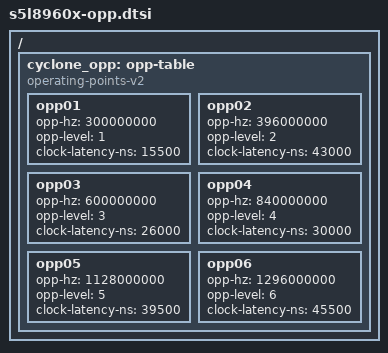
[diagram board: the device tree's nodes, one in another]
// SPDX-License-Identifier: GPL-2.0+ OR MIT
/*
 * Operating points for Apple S5L8960X "A7" SoC, Up to 1296 MHz
 *
 * target-type: N51, N53, J85, J86. J87, J85m, J86m, J87m
 *
 * Copyright (c) 2024, Nick Chan <towinchenmi@gmail.com>
 */

/ {
	cyclone_opp: opp-table {
		compatible = "operating-points-v2";

		opp01 {
			opp-hz = /bits/ 64 <300000000>;
			opp-level = <1>;
			clock-latency-ns = <15500>;
		};
		opp02 {
			opp-hz = /bits/ 64 <396000000>;
			opp-level = <2>;
			clock-latency-ns = <43000>;
		};
		opp03 {
			opp-hz = /bits/ 64 <600000000>;
			opp-level = <3>;
			clock-latency-ns = <26000>;
		};
		opp04 {
			opp-hz = /bits/ 64 <840000000>;
			opp-level = <4>;
			clock-latency-ns = <30000>;
		};
		opp05 {
			opp-hz = /bits/ 64 <1128000000>;
			opp-level = <5>;
			clock-latency-ns = <39500>;
		};
		opp06 {
			opp-hz = /bits/ 64 <1296000000>;
			opp-level = <6>;
			clock-latency-ns = <45500>;
		};
	};
};
